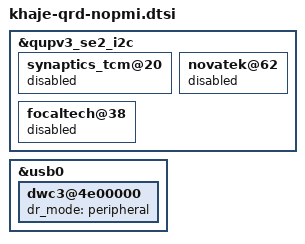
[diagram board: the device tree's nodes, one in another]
#include "khaje-qrd.dtsi"

&qupv3_se2_i2c {
	synaptics_tcm@20 {
		status = "disabled";
	};

	novatek@62 {
		status = "disabled";
	};

	focaltech@38 {
		status = "disabled";
	};
};

&usb0 {
	/delete-property/ extcon;
	dwc3@4e00000 {
		dr_mode = "peripheral";
	};
};
